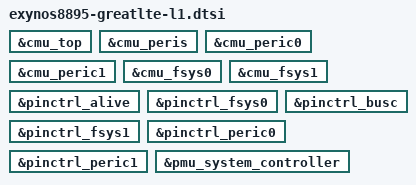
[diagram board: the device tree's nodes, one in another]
// SPDX-License-Identifier: GPL-2.0 OR BSD-3-Clause
/*
 * Samsung Galaxy Note 8 (greatlte, SM-N950N) board DT, part "l1":
 * L1 platform: PMU/PD/pinctrl/watchdog/restart/reboot-mode board parts (L1 4.3-4.7).
 *
 * Included at the end of exynos8895-greatlte.dts, after L0's nodes, in the merge
 * order of FULL_IMAGE_PLAN.md 2.2. Owner: WP-L1; no other work package edits this
 * file (plan 2.3 rule D1). A node that two parts both configure (&usi9, &usi10)
 * is written identically in both files: dtc lets the later file win on a differing
 * value, which gl-verify V-DUP reports as an error. L0's reserved-memory stays in
 * the .dts; carveout additions and flag changes are &label edits here (plan X-8).
 */

/*
 * L1 takes over the nodes L0's bring-up block disables (exynos8895-greatlte.dts,
 * "L0 bring-up" block; gl-verify L-V6 lets layer 1 enable them).
 */

/*
 * The six ACK CMUs (A:arch/arm64/boot/dts/exynos/exynos8895.dtsi:173,216,504,1249,1275,1331),
 * verified against CMUCAL in spec/L1_platform.md 7.1 and carrying L1's gate policy (5.1-5.2):
 * non-IP gates stay in the mode S-Boot left, IP gates go manual.
 */
&cmu_top { status = "okay"; };
&cmu_peris { status = "okay"; };
&cmu_peric0 { status = "okay"; };
&cmu_peric1 { status = "okay"; };
&cmu_fsys0 { status = "okay"; };
&cmu_fsys1 { status = "okay"; };

/*
 * Pin controllers (spec/L1_platform.md 4.6, 7.2: the 35 ACK banks equal stock's; ALIVE,
 * FSYS0, FSYS1, BUSC, PERIC0, PERIC1 = stock FDT:88-100,690-693,862-865,1139-1142,
 * 1212-1215,2000-2003). ABOX and VTS stay off through L0's block (not restated here, plan
 * 2.3 D1 / V-DUP): their registers sit in pd_abox/pd_vts and no FDT consumer references
 * their banks (gph0..gph3 carry no phandle, FDT:497,504,511,619); the audio layer enables
 * them with their domains and the no_pm_save quirk (L6E 5.11).
 */
&pinctrl_alive { status = "okay"; };
&pinctrl_fsys0 { status = "okay"; };
&pinctrl_fsys1 { status = "okay"; };
&pinctrl_busc { status = "okay"; };
&pinctrl_peric0 { status = "okay"; };
&pinctrl_peric1 { status = "okay"; };

/*
 * PMU (spec/L1_platform.md 4.3, 5.7, 5.8a): exynos8895_pmu_data applies stock lpm_init and
 * registers the INFORM2/INFORM3 restart defaults; its children are syscon-reboot (SWRESET),
 * syscon-poweroff (PS_HOLD bit 8) and the INFORM3 reboot-mode node. Stock node:
 * S:arch/arm64/boot/dts/exynos/exynos8895.dtsi:299-302, FDT:4404-4409.
 */
&pmu_system_controller { status = "okay"; };
